# tviibh16m register map
Vendor: Infineon Technologies; Series: TVIIBH16M; File version: 1.0
CPU: CM7 r0p1, little endian, MPU, FPU, double-precision FPU, I-cache, D-cache, VTOR, ITCM, DTCM, 3 interrupt priority bits, 16 interrupts
Registers are 32-bit, read-write, reset 0x0 unless marked. A register's access mark holds for its fields unless they carry their own. Offsets are from the block's base; [hi:lo] are bit positions; lines under a group give offsets from that group.

## SDHC0 (part 1 of 3) — SD/eMMC Host Controller
Base 0x40460000
0x1000 CORE group — MMIO for Synopsys Mobile Storage Host Controller IP
  0x00 SDMASA_R — SDMA System Address register
    [31:0] BLOCKCNT_SDMASA — 32-bit Block Count (SDMA System Address) - SDMA System Address (Host Version 4 Enable = 0): This register contains the system memory address for an SDMA transfer in the 32-bit addressing mode. When the Host Controller stops an SDMA transfer, this register points to the system address of the next contiguous data position. It can be accessed only if no transaction is executing. Reading this register during data transfers may return an invalid value. - 32-bit Block Count (Host Version 4 Enable = 1): From the Host Controller Version 4.10 specification, this register is redefined as 32-bit Block Count. The Host Controller decrements the block count of this register for every block transfer and the data transfer stops when the count reaches zero. This register must be accessed when no transaction is executing. Reading this register during data transfers may return invalid value. Following are the values for BLOCKCNT_SDMASA: - 0xFFFF_FFFF - 4G - 1 Block - ...... - 0x0000_0002 - 2 Blocks - 0x0000_0001 - 1 Block - 0x0000_0000 - Stop Count Note: - When Host Version 4 Enable = 0, SDMA uses this register as system address and hence Auto CMD23 cannot be used with SDMA since this register is assigned for Auto CMD23 as 32-bit Block Count register. -When Host Version 4 Enable = 1, SDMA uses ADMA system address register and this register is reassigned to 32-bit Block Count. This register must be programmed with a non-zero value for data transfer if the 32-bit Block count register is used instead of the 16-bit Block count register. SDMA may use Auto CMD23 if 32-bit Block Count register is used.
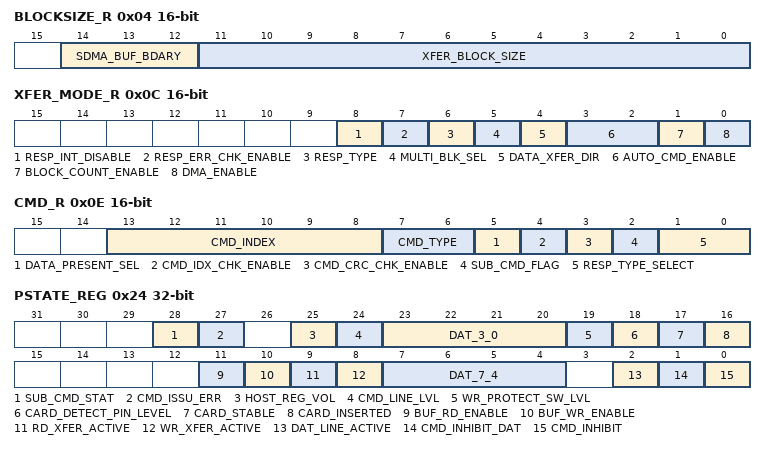
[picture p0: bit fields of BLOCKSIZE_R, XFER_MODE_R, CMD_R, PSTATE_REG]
  0x04 BLOCKSIZE_R 16-bit — Block Size register
    [14:12] SDMA_BUF_BDARY — SDMA Buffer Boundary These bits specify the size of contiguous buffer in system memory. The SDMA transfer waits at every boundary specified by these fields and the Host Controller generates the DMA interrupt to request the Host Driver to update the SDMA System Address register. Values: - 0x0 (BYTES_4K): 4K bytes SDMA Buffer Boundary - 0x1 (BYTES_8K): 8K bytes SDMA Buffer Boundary - 0x2 (BYTES_16K): 16K bytes SDMA Buffer Boundary - 0x3 (BYTES_32K): 32K bytes SDMA Buffer Boundary - 0x4 (BYTES_64K): 64K bytes SDMA Buffer Boundary - 0x5 (BYTES_128K): 128K bytes SDMA Buffer Boundary - 0x6 (BYTES_256K): 256K bytes SDMA Buffer Boundary - 0x7 (BYTES_512K): 512K bytes SDMA Buffer Boundary
    [11:0] XFER_BLOCK_SIZE — Transfer Block Size These bits specify the block size of data transfers. In case of memory, it is set to 512 bytes. It can be accessed only if no transaction is executing. Read operations during transfers may return an invalid value, and write operations are ignored. Following are the values for XFER_BLOCK_SIZE: - 0x1: 1 byte - 0x2: 2 bytes - 0x3: 3 bytes - ...... - 0x1FF: 511 byte - 0x200: 512 bytes - ...... - 0x800: 2048 bytes Note: This register must be programmed with a non-zero value for data transfer.
  0x06 BLOCKCOUNT_R 16-bit — 16-bit Block Count register
    [15:0] BLOCK_CNT — 16-bit Block Count - If the Host Version 4 Enable bit is set 0 or the 16-bit Block Count register is set to non-zero, the 16-bit Block Count register is selected. - If the Host Version 4 Enable bit is set 1 and the 16-bit Block Count register is set to zero, the 32-bit Block Count register is selected. Following are the values for BLOCK_CNT: - 0x0: Stop Count - 0x1: 1 Block - 0x2: 2 Blocks - ... - ... - 0xFFFF: 65535 Blocks Note: For Host Version 4 Enable = 0, this register must be set to 0000h before programming the 32-bit block count register when Auto CMD23 is enabled for non-DMA and ADMA modes.
  0x08 ARGUMENT_R — Argument register
    [31:0] ARGUMENT — Command Argument These bits specify the SD/eMMC command argument that is specified in bits 39-8 of the Command format.
  0x0C XFER_MODE_R 16-bit — Transfer Mode register
    [8] RESP_INT_DISABLE — Response Interrupt Disable The Host Controller supports response check function to avoid overhead of response error check by the Host driver. Response types of only R1 and R5 can be checked by the Controller. If Host Driver checks the response error, set this bit to 0 and wait for Command Complete Interrupt and then check the response register. If the Host Controller checks the response error, set this bit to 1 and set the Response Error Check Enable bit to 1. The Command Complete Interrupt is disabled by this bit regardless of the Command Complete Signal Enable. Values: - 0x0 (ENABLED): Response Interrupt is enabled - 0x1 (DISABLED): Response Interrupt is disabled
    [7] RESP_ERR_CHK_ENABLE — Response Error Check Enable The Host Controller supports response check function to avoid overhead of response error check by Host driver. Response types of only R1 and R5 can be checked by the Controller. If the Host Controller checks the response error, set this bit to 1 and set Response Interrupt Disable to 1. If an error is detected, the Response Error interrupt is generated in the Error Interrupt Status register. Note: - Response error check must not be enabled for any response type other than R1 and R5. Values: - 0x0 (DISABLED): Response Error Check is disabled - 0x1 (ENABLED): Response Error Check is enabled
    [6] RESP_TYPE — Response Type R1/R5 This bit selects either R1 or R5 as a response type when the Response Error Check is selected. Error statuses checked in R1: - OUT_OF_RANGE - ADDRESS_ERROR - BLOCK_LEN_ERROR - WP_VIOLATION - CARD_IS_LOCKED - COM_CRC_ERROR - CARD_ECC_FAILED - CC_ERROR - ERROR Response Flags checked in R5: - COM_CRC_ERROR - ERROR - FUNCTION_NUMBER - OUT_OF_RANGE Values: - 0x0 (RESP_R1): R1 (Memory) - 0x1 (RESP_R5): R5 (SDIO)
    [5] MULTI_BLK_SEL — Multi/Single Block Select This bit is set when issuing multiple-block transfer commands using the DAT line. If this bit is set to 0, it is not necessary to set the Block Count register.
    [4] DATA_XFER_DIR — Data Transfer Direction Select This bit defines the direction of DAT line data transfers. This bit is set to 1 by the Host Driver to transfer data from the SD/eMMC card to the Host Controller and it is set to 0 for all other commands. Values: - 0x1 (READ): Read (Card to Host) - 0x0 (WRITE): Write (Host to Card)
    [3:2] AUTO_CMD_ENABLE — Auto Command Enable This field determines use of Auto Command functions. Note: In SDIO, this field must be set as 00b (Auto Command Disabled). Values: - 0x0 (AUTO_CMD_DISABLED): Auto Command Disabled - 0x1 (AUTO_CMD12_ENABLED): Auto CMD12 Enable - 0x2 (AUTO_CMD23_ENABLED): Auto CMD23 Enable - 0x3 (AUTO_CMD_AUTO_SEL): Auto CMD Auto Select
    [1] BLOCK_COUNT_ENABLE — Block Count Enable This bit is used to enable the Block Count register, which is relevant for multiple block transfers. If this bit is set to 0, the Block Count register is disabled, which is useful in executing an infinite transfer. The Host Driver must set this bit to 0 when ADMA is used. When 16-bit Block Count register is used, the Host Driver can set this bit to 0 in ADMA2 mode to enable larger data transfer than the maximum of 65535 block counts supported by the 16-bit Block Count register.
    [0] DMA_ENABLE — DMA Enable This bit enables the DMA functionality. If this bit is set to 1, a DMA operation begins when the Host Driver writes to the Command register. You can select one of the DMA modes by using DMA Select in the Host Control 1 register. Values: - 0x1 (ENABLED): DMA Data transfer - 0x0 (DISABLED): No data transfer or Non-DMA data transfer
  0x0E CMD_R 16-bit — Command register
    [13:8] CMD_INDEX — Command Index These bits are set to the command number that is specified in bits 45-40 of the Command Format.
    [7:6] CMD_TYPE — Command Type These bits indicate the command type. Note: While issuing Abort CMD using CMD12/CMD52 or reset CMD using CMD0/CMD52, CMD_TYPE field shall be set to 0x3. Values: - 0x3 (ABORT_CMD): Abort - 0x2 (RESUME_CMD): Resume - 0x1 (SUSPEND_CMD): Suspend - 0x0 (NORMAL_CMD): Normal
    [5] DATA_PRESENT_SEL — Data Present Select This bit is set to 1 to indicate that data is present and that the data is transferred using the DAT line. This bit is set to 0 in the following instances: - Command using the CMD line - Command with no data transfer but using busy signal on the DAT[0] line - Resume Command Values: - 0x0 (NO_DATA): No Data Present - 0x1 (DATA): Data Present
    [4] CMD_IDX_CHK_ENABLE — Command Index Check Enable This bit enables the Host Controller to check the index field in the response to verify if it has the same value as the command index. If the value is not the same, it is reported as a Command Index error. Note: - Index Check enable must be set to 0 for the command with no response, R2 response, R3 response and R4 response. Values: - 0x0 (DISABLED): Disable - 0x1 (ENABLED): Enable
    [3] CMD_CRC_CHK_ENABLE — Command CRC Check Enable This bit enables the Host Controller to check the CRC field in the response. If an error is detected, it is reported as a Command CRC error. Note: - CRC Check enable must be set to 0 for the command with no response, R3 response, and R4 response. Values: - 0x0 (DISABLED): Disable - 0x1 (ENABLED): Enable
    [2] SUB_CMD_FLAG — Sub Command Flag This bit distinguishes between a main command and a sub command. Values: - 0x0 (MAIN): Main Command - 0x1 (SUB): Sub Command
    [1:0] RESP_TYPE_SELECT — Response Type Select This bit indicates the type of response expected from the card. Values: - 0x0 (NO_RESP): No Response - 0x1 (RESP_LEN_136): Response Length 136 - 0x2 (RESP_LEN_48): Response Length 48 - 0x3 (RESP_LEN_48B): Response Length 48; Check Busy after response
  0x10 RESP01_R ro — Response Register 0/1
    [31:0] RESP01 — Command Response These bits reflect 39-8 bits of SD/eMMC Response Field. Note: For Auto CMD, the 32-bit response (bits 39-8 of the Response Field) is updated in the RESP67_R register.
  0x14 RESP23_R ro — Response Register 2/3
    [31:0] RESP23 — Command Response These bits reflect 71-40 bits of the SD/eMMC Response
  0x18 RESP45_R ro — Response Register 4/5
    [31:0] RESP45 — Command Response These bits reflect 103-72 bits of the Response Field.
  0x1C RESP67_R ro — Response Register 6/7
    [31:0] RESP67 — Command Response These bits reflect bits 135-104 of SD/EMMC Response Field. Note: For Auto CMD, this register also reflects the 32-bit response (bits 39-8 of the Response Field).
  0x20 BUF_DATA_R — Buffer Data Port Register
    [31:0] BUF_DATA — Buffer Data These bits enable access to the Host Controller packet buffer.
  0x24 PSTATE_REG ro — Present State Register
    [28] SUB_CMD_STAT — Sub Command Status This bit is used to distinguish between a main command and a sub command status. Values: - 0x0 (FALSE): Main Command Status - 0x1 (TRUE): Sub Command Status
    [27] CMD_ISSU_ERR — Command Not Issued by Error This bit is set if a command cannot be issued after setting the command register due to an error except the Auto CMD12 error. Values: - 0x0 (FALSE): No error for issuing a command - 0x1 (TRUE): Command cannot be issued
    [25] HOST_REG_VOL — Host Regulator Voltage Stable This bit is used to check whether the host regulator voltage is stable for switching the voltage of UHS-I mode. This bit reflects the synchronized value of the host_reg_vol_stable signal. Values: - 0x0 (FALSE): Host Regulator Voltage is not stable - 0x1 (TRUE): Host Regulator Voltage is stable
    [24] CMD_LINE_LVL — Command-Line Signal Level This bit is used to check the CMD line level to recover from errors and for debugging. These bits reflect the value of the sd_cmd_in signal.
    [23:20] DAT_3_0 — DAT[3:0] Line Signal Level This bit is used to check the DAT line level to recover from errors and for debugging. These bits reflect the value of the sd_dat_in (lower nibble) signal.
    [19] WR_PROTECT_SW_LVL — Write Protect Switch Pin Level This bit is supported only for memory and combo cards. This bit reflects the synchronized value of the card_write_prot signal. Values: - 0x0 (FALSE): Write protected - 0x1 (TRUE): Write enabled
    [18] CARD_DETECT_PIN_LEVEL — Card Detect Pin Level This bit reflects the inverse synchronized value of the card_detect_n signal. Values: - 0x0 (FALSE): No card present - 0x1 (TRUE): Card Present
    [17] CARD_STABLE — Card Stable This bit indicates the stability of the Card Detect Pin Level. A card is not detected if this bit is set to 1 and the value of the CARD_INSERTED bit is 0. Values: - 0x0 (FALSE): Reset or Debouncing - 0x1 (TRUE): No Card or Inserted
    [16] CARD_INSERTED — Card Inserted This bit indicates whether a card has been inserted. The Host Controller debounces this signal so that Host Driver need not wait for it to stabilize. Values: - 0x0 (FALSE): Reset, Debouncing, or No card - 0x1 (TRUE): Card Inserted
    [11] BUF_RD_ENABLE — Buffer Read Enable This bit is used for non-DMA transfers. This bit is set if valid data exists in the Host buffer. Values: - 0x0 (DISABLED): Read disable - 0x1 (ENABLED): Read enable
    [10] BUF_WR_ENABLE — Buffer Write Enable This bit is used for non-DMA transfers. This bit is set if space is available for writing data. Values: - 0x0 (DISABLED): Write disable - 0x1 (ENABLED): Write enable
    [9] RD_XFER_ACTIVE — Read Transfer Active This bit indicates whether a read transfer is active for SD/eMMC mode. Values: - 0x0 (INACTIVE): No valid data - 0x1 (ACTIVE): Transferring data
    [8] WR_XFER_ACTIVE — Write Transfer Active This status indicates whether a write transfer is active for SD/eMMC mode. Values: - 0x0 (INACTIVE): No valid data - 0x1 (ACTIVE): Transferring data
    [7:4] DAT_7_4 — DAT[7:4] Line Signal Level This bit is used to check the DAT line level to recover from errors and for debugging. These bits reflect the value of the sd_dat_in (upper nibble) signal.
    [2] DAT_LINE_ACTIVE — DAT Line Active (SD/eMMC Mode only) This bit indicates whether one of the DAT lines on the SD/eMMC bus is in use. In the case of read transactions, this bit indicates whether a read transfer is executing on the SD/eMMC bus. In the case of write transactions, this bit indicates whether a write transfer is executing on the SD/eMMC bus. For a command with busy, this status indicates whether the command executing busy is executing on an SD or eMMC bus. Values: - 0x0 (INACTIVE): DAT Line Inactive - 0x1 (ACTIVE): DAT Line Active
    [1] CMD_INHIBIT_DAT — Command Inhibit (DAT) This bit is applicable for SD/eMMC mode and is generated if either DAT line active or Read transfer active is set to 1. If this bit is set to 0, it indicates that the Host Controller can issue subsequent SD/eMMC commands. Values: - 0x0 (READY): Can issue command which used DAT line - 0x1 (NOT_READY): Cannot issue command which used DAT line
    [0] CMD_INHIBIT — Command Inhibit (CMD) This bit indicates the following : - SD/eMMC mode: If this bit is set to 0, it indicates that the CMD line is not in use and the Host controller can issue an SD/eMMC command using the CMD line. This bit is set when the command register is written. This bit is cleared when the command response is received. This bit is not cleared by the response of auto CMD12/23 but cleared by the response of read/write command. Values: - 0x0 (READY): Host Controller is ready to issue a command - 0x1 (NOT_READY): Host Controller is not ready to issue a command
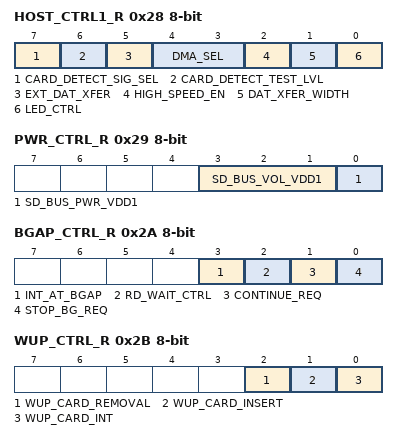
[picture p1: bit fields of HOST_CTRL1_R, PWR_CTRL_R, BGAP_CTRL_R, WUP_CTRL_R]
  0x28 HOST_CTRL1_R 8-bit — Host Control 1 Register
    [7] CARD_DETECT_SIG_SEL — Card Detect Signal Selection This bit selects a source for card detection. When the source for the card detection is switched, the interrupt must be disabled during the switching period. Values: - 0x1 (CARD_DT_TEST_LEVEL): Card Detect Test Level is selected (for test purpose) - 0x0 (card_detect_n): card_detect_n signal is selected (for normal use)
    [6] CARD_DETECT_TEST_LVL — Card Detect Test Level This bit is enabled while the Card Detect Signal Selection is set to 1 and it indicates whether a card inserted or not. Values: - 0x1 (CARD_INSERTED): Card Inserted - 0x0 (No_CARD): No Card
    [5] EXT_DAT_XFER — Extended Data Transfer Width This bit controls 8-bit bus width mode of embedded device. Values: - 0x1 (EIGHT_BIT): 8-bit Bus Width - 0x0 (DEFAULT): Bus Width is selected by the Data Transfer Width
    [4:3] DMA_SEL
    [2] HIGH_SPEED_EN — High Speed Enable (SD/eMMC Mode only) Before setting this bit, the Host Driver checks the High Speed Support in the Capabilities register. Note: SDHC always outputs the sd_cmd_out and sd_dat_out lines at the rising edge of card clock irrespective of this bit. Values: - 0x1 (HIGH_SPEED): High Speed mode - 0x0 (NORMAL_SPEED): Normal Speed mode
    [1] DAT_XFER_WIDTH — Data Transfer Width For SD/eMMC mode,this bit selects the data transfer width of the Host Controller. The Host Driver sets it to match the data width of the SD/eMMC card. Values: - 0x1 (FOUR_BIT): 4-bit mode - 0x0 (ONE_BIT): 1-bit mode
    [0] LED_CTRL — LED Control This bit is used to caution the user not to remove the card while the SD card is being accessed. The value is reflected on the led_ctrl ouput. Values: - 0x0 (OFF): LED off - 0x1 (ON): LED on
  0x29 PWR_CTRL_R 8-bit — Power Control Register
    [3:1] SD_BUS_VOL_VDD1 — These bits are NON-operational (they can be written and read but they have no effect). In a generic HCI host these would select the card supply voltage. But, for the applications targeted for this block it is assumed that the card supply voltage is always fixed at the board level. If for some reason there is a variable power supply then that can be managed through normal GPIO programming separately.
    [0] SD_BUS_PWR_VDD1 — SD Bus Power for VDD1 This bit enables VDD1 power of the card. This setting is available on the card_if_pwr_en output so that it can be used to control the VDD1 power supply of the card. Before setting this bit, the SD Host Driver sets the SD Bus Voltage Select bit. If the Host Controller detects a No Card state, this bit is cleared. In SD mode, if this bit is cleared, the Host Controller stops the SD Clock by clearing the SD_CLK_IN bit in the CLK_CTRL_R register. Values: - 0x0 (OFF): Power off - 0x1 (ON): Power on
  0x2A BGAP_CTRL_R 8-bit — Block Gap Control Register
    [3] INT_AT_BGAP — Interrupt At Block Gap This bit is valid only in the 4-bit mode of an SDIO card and is used to select a sample point in the interrupt cycle. Setting to 1 enables interrupt detection at the block gap for a multiple block transfer. Values: - 0x0 (DISABLE): Disabled - 0x1 (ENABLE): Enabled
    [2] RD_WAIT_CTRL
    [1] CONTINUE_REQ — Continue Request This bit is used to restart the transaction, which was stopped using the Stop At Block Gap Request. The Host Controller automatically clears this bit when the transaction restarts. If stop at block gap request is set to 1, any write to this bit is ignored. Values: - 0x0 (NO_AFFECT): No Affect - 0x1 (RESTART): Restart
    [0] STOP_BG_REQ — Stop At Block Gap Request This bit is used to stop executing read and write transactions at the next block gap for non-DMA, SDMA, and ADMA transfers. Values: - 0x0 (XFER): Transfer - 0x1 (STOP): Stop
  0x2B WUP_CTRL_R 8-bit — Wakeup Control Register
    [2] WUP_CARD_REMOVAL — Wakeup Event Enable on SD Card Removal This bit enables wakeup event through Card Removal assertion in the Normal Interrupt Status register. For the SDIO card, Wake Up Support (FN_WUS) in the Card Information Structure (CIS) register does not affect this bit. Values: - 0x0 (DISABLED): Disable - 0x1 (ENABLED): Enable
    [1] WUP_CARD_INSERT — Wakeup Event Enable on SD Card Insertion This bit enables wakeup event through Card Insertion assertion in the Normal Interrupt Status register. FN_WUS (Wake Up Support) in CIS does not affect this bit. Values: - 0x0 (DISABLED): Disable - 0x1 (ENABLED): Enable
    [0] WUP_CARD_INT — Wakeup Event Enable on SDIO Card Interrupt (through DAT[1]). This bit enables wakeup event through an SDIO Card Interrupt assertion in the Normal Interrupt Status register. This bit can be set to 1 if FN_WUS (Wake Up Support) in CIS is set to 1. Values: - 0x0 (DISABLED): Disable - 0x1 (ENABLED): Enable
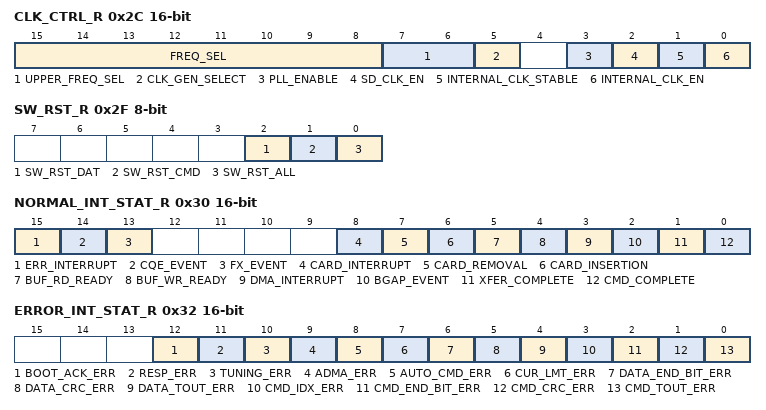
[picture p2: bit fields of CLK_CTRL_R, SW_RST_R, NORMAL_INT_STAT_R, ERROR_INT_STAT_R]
  0x2C CLK_CTRL_R 16-bit — Clock Control Register
    [15:8] FREQ_SEL — SDCLK Frequency Select These bits are used to select the frequency of the SDCLK signal. 10-bit Divided Clock Mode: - 0x3FF - 1/2046 Divided clock - .......... - N - 1/2N Divided Clock - .......... - 0x002 - 1/4 Divided Clock - 0x001 - 1/2 Divided Clock - 0x000 - Base clock (10MHz - 255 MHz)
    [7:6] UPPER_FREQ_SEL — These bits specify the upper 2 bits of 10-bit SDCLK Frequency Select control.
    [5] CLK_GEN_SELECT — Clock Generator Select This bit is used to select the clock generator mode in SDCLK Frequency Select. Values: - 0x0 (FALSE): Divided Clock Mode - 0x1 (TRUE): Programmable Clock Mode
    [3] PLL_ENABLE — PLL Enable This bit is used to activate the PLL (applicable when Host Version 4 Enable = 1). Values: - 0x0 (FALSE): PLL is in low power mode - 0x1 (TRUE): PLL is enabled
    [2] SD_CLK_EN — SD/eMMC Clock Enable This bit stops the clk_card output when set to 0. The SDCLK Frequency Select bit can be changed when this bit is set to 0. Values: - 0x0 (FALSE): Disable providing clk_card - 0x1 (TRUE): Enable providing clk_card
    [1] INTERNAL_CLK_STABLE ro — Internal Clock Stable This bit enables the Host Driver to check the clock stability twice after the Internal Clock Enable bit is set and after the PLL Enable bit is set. This bit reflects the synchronized value of the Internal Clock Stable signal after the Internal Clock Enable bit is set to 1 and also reflects the synchronized value of the Card Clock Stable signal after the PLL Enable bit is set to 1. Values: - 0x0 (FALSE): Not Ready - 0x1 (TRUE): Ready
    [0] INTERNAL_CLK_EN — Internal Clock Enable This bit is set to 0 when the Host Driver is not using the Host Controller or the Host Controller awaits a wakeup interrupt. The Host Controller must stop its internal clock to enter a very low power state. Certain registers are not accessible when this bit is off. So, to be safe turn it on for any register access. Values: - 0x0 (FALSE): Stop - 0x1 (TRUE): Oscillate
  0x2E TOUT_CTRL_R 8-bit — Timeout Control Register
    [3:0] TOUT_CNT
  0x2F SW_RST_R 8-bit — Software Reset Register
    [2] SW_RST_DAT — Software Reset For DAT line This bit is used in SD/eMMC mode and it resets only a part of the data circuit and the DMA circuit is also reset. The following registers and bits are cleared by this bit: - Buffer Data Port register - Buffer is cleared and initialized. - Present state register - Buffer Read Enable - Buffer Write Enable - Read Transfer Active - Write Transfer Active - DAT Line Active - Command Inhibit (DAT) - Block Gap Control register - Continue Request - Stop At Block Gap Request - Normal Interrupt status register - Buffer Read Ready - Buffer Write Ready - DMA Interrupt - Block Gap Event - Transfer Complete Values: - 0x0 (FALSE): Work - 0x1 (TRUE): Reset
    [1] SW_RST_CMD — Software Reset For CMD line This bit resets only a part of the command circuit to be able to issue a command. This reset is effective only for a command issuing circuit (including response error statuses related to Command Inhibit (CMD) control) and does not affect the data transfer circuit. Host Controller can continue data transfer even after this reset is executed while handling subcommand-response errors. The following registers and bits are cleared by this bit: - Present State register - Command Inhibit (CMD) bit - Normal Interrupt Status register - Command Complete bit - Error Interrupt Status - Response error statuses related to Command Inhibit (CMD) bit Values: - 0x0 (FALSE): Work - 0x1 (TRUE): Reset
    [0] SW_RST_ALL — Software Reset For All This reset affects the entire Host Controller except for the card detection circuit. During its initialization, the Host Driver sets this bit to 1 to reset the Host Controller. All registers are reset except the capabilities register. If this bit is set to 1, the Host Driver must issue reset command and reinitialize the card. Values: - 0x0 (FALSE): Work - 0x1 (TRUE): Reset
  0x30 NORMAL_INT_STAT_R 16-bit — Normal Interrupt Status Register
    [15] ERR_INTERRUPT ro — Error Interrupt If any of the bits in the Error Interrupt Status register are set, then this bit is set. Values: - 0x0 (FALSE): No Error - 0x1 (TRUE): Error
    [14] CQE_EVENT write-1-clears — Command Queuing Event This status is set if Command Queuing/Crypto related event has occurred in eMMC/SD mode. Read CQHCI's CQIS/CRNQIS register for more details. In UHS-II Mode, this bit is irrelevant. Values: - 0x0 (FALSE): No Event - 0x1 (TRUE): Command Queuing Event is detected
    [13] FX_EVENT ro — FX Event This status is set when R[14] of response register is set to 1 and Response Type R1/R5 is set to 0 in Transfer Mode register. This interrupt is used with response check function. Values: - 0x0 (FALSE): No Event - 0x1 (TRUE): FX Event is detected
    [8] CARD_INTERRUPT ro — Card Interrupt This bit reflects the synchronized value of: - DAT[1] Interrupt Input for SD Mode Values: - 0x0 (FALSE): No Card Interrupt - 0x1 (TRUE): Generate Card Interrupt
    [7] CARD_REMOVAL write-1-clears — Card Removal This bit is set if the Card Inserted in the Present State register changes from 1 to 0. Values: - 0x0 (FALSE): Card state stable or Debouncing - 0x1 (TRUE): Card Removed
    [6] CARD_INSERTION write-1-clears — Card Insertion This bit is set if the Card Inserted in the Present State register changes from 0 to 1. Values: - 0x0 (FALSE): Card state stable or Debouncing - 0x1 (TRUE): Card Inserted
    [5] BUF_RD_READY write-1-clears — Buffer Read Ready This bit is set if the Buffer Read Enable changes from 0 to 1. Values: - 0x0 (FALSE): Not ready to read buffer - 0x1 (TRUE): Ready to read buffer
    [4] BUF_WR_READY write-1-clears — Buffer Write Ready This bit is set if the Buffer Write Enable changes from 0 to 1. Values: - 0x0 (FALSE): Not ready to write buffer - 0x1 (TRUE): Ready to write buffer
    [3] DMA_INTERRUPT write-1-clears — DMA Interrupt This bit is set if the Host Controller detects the SDMA Buffer Boundary during transfer. In case of ADMA, by setting the Int field in the descriptor table, the Host controller generates this interrupt. This interrupt is not generated after a Transfer Complete. Values: - 0x0 (FALSE): No DMA Interrupt - 0x1 (TRUE): DMA Interrupt is generated
    [2] BGAP_EVENT write-1-clears — Block Gap Event This bit is set when both read/write transaction is stopped at block gap due to a Stop at Block Gap Request. Values: - 0x0 (FALSE): No Block Gap Event - 0x1 (TRUE): Transaction stopped at block gap
    [1] XFER_COMPLETE write-1-clears — Transfer Complete This bit is set when a read/write transfer and a command with status busy is completed. Values: - 0x0 (FALSE): Not complete - 0x1 (TRUE): Command execution is completed
    [0] CMD_COMPLETE write-1-clears — Command Complete In an SD/eMMC Mode, this bit is set when the end bit of a response except for Auto CMD12 and Auto CMD23. This interrupt is not generated when the Response Interrupt Disable in Transfer Mode Register is set to 1. Values: - 0x0 (FALSE): No command complete - 0x1 (TRUE): Command Complete
  0x32 ERROR_INT_STAT_R 16-bit — Error Interrupt Status Register
    [12] BOOT_ACK_ERR write-1-clears — Boot Acknowledgement Error This bit is set when there is a timeout for boot acknowledgement or when detecting boot ack status having a value other than 010. This is applicable only when boot acknowledgement is expected in eMMC mode. In SD mode, this bit is irrelevant. Values: - 0x0 (FALSE): No error - 0x1 (TRUE): Error
    [11] RESP_ERR write-1-clears — Response Error Host Controller Version 4.00 supports response error check function to avoid overhead of response error check by Host Driver during DMA execution. If Response Error Check Enable is set to 1 in the Transfer Mode register, Host Controller Checks R1 or R5 response. If an error is detected in a response, this bit is set to 1.This is applicable in SD/eMMC mode. Values: - 0x0 (FALSE): No error - 0x1 (TRUE): Error
    [10] TUNING_ERR write-1-clears
    [9] ADMA_ERR write-1-clears — ADMA Error This bit is set when the Host Controller detects error during ADMA-based data transfer. The error could be due to following reasons: - Error response received from System bus (Master I/F) - ADMA3,ADMA2 Descriptors invalid - CQE Task or Transfer descriptors invalid When the error occurs, the state of the ADMA is saved in the ADMA Error Status register. In eMMC CQE mode: The Host Controller generates this Interrupt when it detects an invalid descriptor data (Valid=0) at the ST_FDS state. ADMA Error State in the ADMA Error Status indicates that an error has occurred in ST_FDS state. The Host Driver may find that Valid bit is not set at the error descriptor. Values: - 0x0 (FALSE): No error - 0x1 (TRUE): Error
    [8] AUTO_CMD_ERR write-1-clears — Auto CMD Error This error status is used by Auto CMD12 and Auto CMD23 in SD/eMMC mode. This bit is set when detecting that any of the bits D00 to D05 in Auto CMD Error Status register has changed from 0 to 1. D07 is effective in case of Auto CMD12. Auto CMD Error Status register is valid while this bit is set to 1 and may be cleared by clearing of this bit. Values: - 0x0 (FALSE): No error - 0x1 (TRUE): Error
    [7] CUR_LMT_ERR write-1-clears — Current Limit Error By setting the SD Bus Power bit in the Power Control register, the Host Controller is requested to supply power for the SD Bus. If the Host Controller supports the Current Limit function, it can be protected from an illegal card by stopping power supply to the card in which case this bit indicates a failure status. A reading of 1 for this bit means that the Host Controller is not supplying power to the SD card due to some failure. A reading of 0 for this bit means that the Host Controller is supplying power and no error has occurred. The Host Controller may require some sampling time to detect the current limit. DWC_mshc Host Controller does not support this function, this bit is always set to 0. Values: - 0x0 (FALSE): No error - 0x1 (TRUE): Power Fail
    [6] DATA_END_BIT_ERR write-1-clears — Data End Bit Error This error occurs in SD/eMMC mode either when detecting 0 at the end bit position of read data that uses the DAT line or at the end bit position of the CRC status. Values: - 0x0 (FALSE): No error - 0x1 (TRUE): Error
    [5] DATA_CRC_ERR write-1-clears — Data CRC Error This error occurs in SD/eMMC mode when detecting CRC error when transferring read data which uses the DAT line, when detecting the Write CRC status having a value of other than 010 or when write CRC status timeout. Values: - 0x0 (FALSE): No error - 0x1 (TRUE): Error
    [4] DATA_TOUT_ERR write-1-clears — Data Timeout Error This bit is set in SD/eMMC mode when detecting one of the following timeout conditions: - Busy timeout for R1b, R5b type - Busy timeout after Write CRC status - Write CRC Status timeout - Read Data timeout Values: - 0x0 (FALSE): No error - 0x1 (TRUE): Time out
    [3] CMD_IDX_ERR write-1-clears — Command Index Error This bit is set if a Command Index error occurs in the command respons in SD/eMMC mode. Values: - 0x0 (FALSE): No error - 0x1 (TRUE): Error
    [2] CMD_END_BIT_ERR write-1-clears — Command End Bit Error This bit is set when detecting that the end bit of a command response is 0 in SD/eMMC mode. Values: - 0x0 (FALSE): No error - 0x1 (TRUE): End Bit error generated
    [1] CMD_CRC_ERR write-1-clears — Command CRC Error Command CRC Error is generated in SD/eMMC mode for following two cases. - If a response is returned and the Command Timeout Error is set to 0 (indicating no timeout), this bit is set to 1 when detecting a CRC error in the command response. - The Host Controller detects a CMD line conflict by monitoring the CMD line when a command is issued. If the Host Controller drives the CMD line to 1 level, but detects 0 level on the CMD line at the next SD clock edge, then the Host Controller aborts the command (stop driving CMD line) and set this bit to 1. The Command Timeout Error is also set to 1 to distinguish a CMD line conflict. Values: - 0x0 (FALSE): No error - 0x1 (TRUE): CRC error generated
    [0] CMD_TOUT_ERR write-1-clears — Command Timeout Error In SD/eMMC Mode,this bit is set only if no response is returned within 64 SD clock cycles from the end bit of the command. If the Host Controller detects a CMD line conflict, along with Command CRC Error bit, this bit is set to 1, without waiting for 64 SD/eMMC card clock cycles. Values: - 0x0 (FALSE): No error - 0x1 (TRUE): Time out
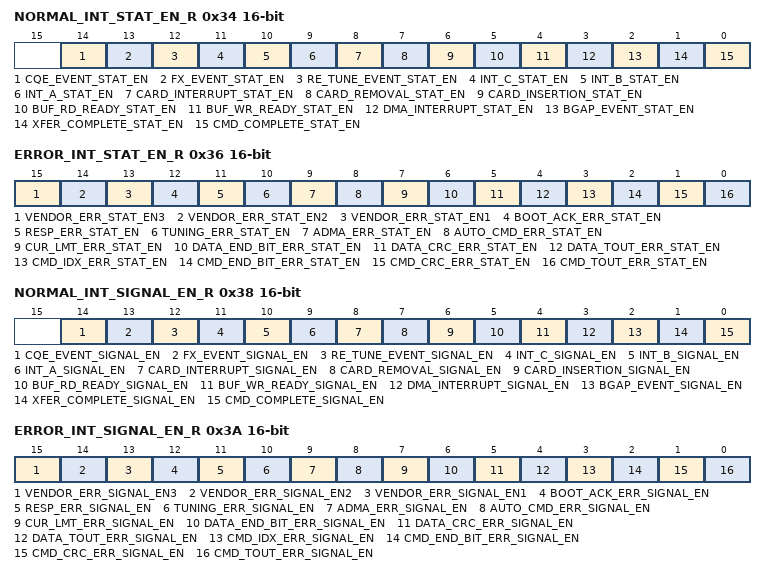
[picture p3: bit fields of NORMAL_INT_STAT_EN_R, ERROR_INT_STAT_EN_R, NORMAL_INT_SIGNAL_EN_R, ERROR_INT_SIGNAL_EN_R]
  0x34 NORMAL_INT_STAT_EN_R 16-bit — Normal Interrupt Status Enable Register
    [14] CQE_EVENT_STAT_EN — CQE Event Status Enable Values: - 0x0 (FALSE): Masked - 0x1 (TRUE): Enabled
    [13] FX_EVENT_STAT_EN — FX Event Status Enable This bit is added from Version 4.10. Values: - 0x0 (FALSE): Masked - 0x1 (TRUE): Enabled
    [12] RE_TUNE_EVENT_STAT_EN
    [11] INT_C_STAT_EN
    [10] INT_B_STAT_EN
    [9] INT_A_STAT_EN
    [8] CARD_INTERRUPT_STAT_EN — Card Interrupt Status Enable If this bit is set to 0, the Host Controller clears the interrupt request to the System. The Card Interrupt detection is stopped when this bit is cleared and restarted when this bit is set to 1. The Host Driver may clear the Card Interrupt Status Enable before servicing the Card Interrupt and may set this bit again after all interrupt requests from the card are cleared to prevent inadvertent interrupts. Values: - 0x0 (FALSE): Masked - 0x1 (TRUE): Enabled
    [7] CARD_REMOVAL_STAT_EN — Card Removal Status Enable Values: - 0x0 (FALSE): Masked - 0x1 (TRUE): Enabled
    [6] CARD_INSERTION_STAT_EN — Card Insertion Status Enable Values: - 0x0 (FALSE): Masked - 0x1 (TRUE): Enabled
    [5] BUF_RD_READY_STAT_EN — Buffer Read Ready Status Enable Values: - 0x0 (FALSE): Masked - 0x1 (TRUE): Enabled
    [4] BUF_WR_READY_STAT_EN — Buffer Write Ready Status Enable Values: - 0x0 (FALSE): Masked - 0x1 (TRUE): Enabled
    [3] DMA_INTERRUPT_STAT_EN — DMA Interrupt Status Enable Values: - 0x0 (FALSE): Masked - 0x1 (TRUE): Enabled
    [2] BGAP_EVENT_STAT_EN — Block Gap Event Status Enable Values: - 0x0 (FALSE): Masked - 0x1 (TRUE): Enabled
    [1] XFER_COMPLETE_STAT_EN — Transfer Complete Status Enable Values: - 0x0 (FALSE): Masked - 0x1 (TRUE): Enabled
    [0] CMD_COMPLETE_STAT_EN — Command Complete Status Enable Values: - 0x0 (FALSE): Masked - 0x1 (TRUE): Enabled
  0x36 ERROR_INT_STAT_EN_R 16-bit — Error Interrupt Status Enable Register
    [15] VENDOR_ERR_STAT_EN3
    [14] VENDOR_ERR_STAT_EN2
    [13] VENDOR_ERR_STAT_EN1
    [12] BOOT_ACK_ERR_STAT_EN — Boot Acknowledgment Error (eMMC Mode only) Setting this bit to 1 enables setting of Boot Acknowledgment Error in Error Interrupt Status register (ERROR_INT_STAT_R). Values: - 0x0 (FALSE): Masked - 0x1 (TRUE): Enabled
    [11] RESP_ERR_STAT_EN — Response Error Status Enable (SD Mode only) Values: - 0x0 (FALSE): Masked - 0x1 (TRUE): Enabled
    [10] TUNING_ERR_STAT_EN — Tuning Error Status Enable (UHS-I Mode only) Values: - 0x0 (FALSE): Masked - 0x1 (TRUE): Enabled
    [9] ADMA_ERR_STAT_EN — ADMA Error Status Enable Values: - 0x0 (FALSE): Masked - 0x1 (TRUE): Enabled
    [8] AUTO_CMD_ERR_STAT_EN — Auto CMD Error Status Enable (SD/eMMC Mode only). Values: - 0x0 (FALSE): Masked - 0x1 (TRUE): Enabled
    [7] CUR_LMT_ERR_STAT_EN — Current Limit Error Status Enable Values: - 0x0 (FALSE): Masked - 0x1 (TRUE): Enabled
    [6] DATA_END_BIT_ERR_STAT_EN — Data End Bit Error Status Enable (SD/eMMC Mode only). Values: - 0x0 (FALSE): Masked - 0x1 (TRUE): Enabled
    [5] DATA_CRC_ERR_STAT_EN — Data CRC Error Status Enable (SD/eMMC Mode only) Values: - 0x0 (FALSE): Masked - 0x1 (TRUE): Enabled
    [4] DATA_TOUT_ERR_STAT_EN — Data Timeout Error Status Enable (SD/eMMC Mode only) Values: - 0x0 (FALSE): Masked - 0x1 (TRUE): Enabled
    [3] CMD_IDX_ERR_STAT_EN — Command Index Error Status Enable (SD/eMMC Mode only) Values: - 0x0 (FALSE): Masked - 0x1 (TRUE): Enabled
    [2] CMD_END_BIT_ERR_STAT_EN — Command End Bit Error Status Enable (SD/eMMC Mode only) Values: - 0x0 (FALSE): Masked - 0x1 (TRUE): Enabled
    [1] CMD_CRC_ERR_STAT_EN — ommand CRC Error Status Enable (SD/eMMC Mode only) Values: - 0x0 (FALSE): Masked - 0x1 (TRUE): Enabled
    [0] CMD_TOUT_ERR_STAT_EN — Command Timeout Error Status Enable (SD/eMMC Mode only). Values: - 0x0 (FALSE): Masked - 0x1 (TRUE): Enabled
  0x38 NORMAL_INT_SIGNAL_EN_R 16-bit — Normal Interrupt Signal Enable Register
    [14] CQE_EVENT_SIGNAL_EN — Command Queuing Engine Event Signal Enable Values: - 0x0 (FALSE): Masked - 0x1 (TRUE): Enabled
    [13] FX_EVENT_SIGNAL_EN — FX Event Signal Enable Values: - 0x0 (FALSE): Masked - 0x1 (TRUE): Enabled
    [12] RE_TUNE_EVENT_SIGNAL_EN
    [11] INT_C_SIGNAL_EN
    [10] INT_B_SIGNAL_EN
    [9] INT_A_SIGNAL_EN
    [8] CARD_INTERRUPT_SIGNAL_EN — Card Interrupt Signal Enable Values: - 0x0 (FALSE): Masked - 0x1 (TRUE): Enabled
    [7] CARD_REMOVAL_SIGNAL_EN — Card Removal Signal Enable Values: - 0x0 (FALSE): Masked - 0x1 (TRUE): Enabled
    [6] CARD_INSERTION_SIGNAL_EN — Card Insertion Signal Enable Values: - 0x0 (FALSE): Masked - 0x1 (TRUE): Enabled
    [5] BUF_RD_READY_SIGNAL_EN — Buffer Read Ready Signal Enable Values: - 0x0 (FALSE): Masked - 0x1 (TRUE): Enabled
    [4] BUF_WR_READY_SIGNAL_EN — Buffer Write Ready Signal Enable Values: - 0x0 (FALSE): Masked - 0x1 (TRUE): Enabled
    [3] DMA_INTERRUPT_SIGNAL_EN — DMA Interrupt Signal Enable Values: - 0x0 (FALSE): Masked - 0x1 (TRUE): Enabled
    [2] BGAP_EVENT_SIGNAL_EN — Block Gap Event Signal Enable Values: - 0x0 (FALSE): Masked - 0x1 (TRUE): Enabled
    [1] XFER_COMPLETE_SIGNAL_EN — Transfer Complete Signal Enable Values: - 0x0 (FALSE): Masked - 0x1 (TRUE): Enabled
    [0] CMD_COMPLETE_SIGNAL_EN — Command Complete Signal Enable Values: - 0x0 (FALSE): Masked - 0x1 (TRUE): Enabled
  0x3A ERROR_INT_SIGNAL_EN_R 16-bit — Error Interrupt Signal Enable Register
    [15] VENDOR_ERR_SIGNAL_EN3
    [14] VENDOR_ERR_SIGNAL_EN2
    [13] VENDOR_ERR_SIGNAL_EN1
    [12] BOOT_ACK_ERR_SIGNAL_EN — Boot Acknowledgment Error (eMMC Mode only). Setting this bit to 1 enables generating interrupt signal when Boot Acknowledgement Error in Error Interrupt Status register is set. Values: - 0x0 (FALSE): Masked - 0x1 (TRUE): Enabled
    [11] RESP_ERR_SIGNAL_EN — Response Error Signal Enable (SD Mode only) Values: - 0x0 (FALSE): Masked - 0x1 (TRUE): Enabled
    [10] TUNING_ERR_SIGNAL_EN
    [9] ADMA_ERR_SIGNAL_EN — ADMA Error Signal Enable Values: - 0x0 (FALSE): Masked - 0x1 (TRUE): Enabled
    [8] AUTO_CMD_ERR_SIGNAL_EN — Auto CMD Error Signal Enable (SD/eMMC Mode only) Values: - 0x0 (FALSE): Masked - 0x1 (TRUE): Enabled
    [7] CUR_LMT_ERR_SIGNAL_EN — Current Limit Error Signal Enable Values: - 0x0 (FALSE): Masked - 0x1 (TRUE): Enabled
    [6] DATA_END_BIT_ERR_SIGNAL_EN — Data End Bit Error Signal Enable (SD/eMMC Mode only) Values: - 0x0 (FALSE): Masked - 0x1 (TRUE): Enabled
    [5] DATA_CRC_ERR_SIGNAL_EN — Data CRC Error Signal Enable (SD/eMMC Mode only) Values: - 0x0 (FALSE): Masked - 0x1 (TRUE): Enabled
    [4] DATA_TOUT_ERR_SIGNAL_EN — Data Timeout Error Signal Enable (SD/eMMC Mode only) Values: - 0x0 (FALSE): Masked - 0x1 (TRUE): Enabled
    [3] CMD_IDX_ERR_SIGNAL_EN — Command Index Error Signal Enable (SD/eMMC Mode only) Values: - 0x0 (FALSE): No error - 0x1 (TRUE): Error
    [2] CMD_END_BIT_ERR_SIGNAL_EN — Command End Bit Error Signal Enable (SD/eMMC Mode only) Values: - 0x0 (FALSE): Masked - 0x1 (TRUE): Enabled
    [1] CMD_CRC_ERR_SIGNAL_EN — Command CRC Error Signal Enable (SD/eMMC Mode only) Values: - 0x0 (FALSE): Masked - 0x1 (TRUE): Enabled
    [0] CMD_TOUT_ERR_SIGNAL_EN — Command Timeout Error Signal Enable (SD/eMMC Mode only) Values: - 0x0 (FALSE): Masked - 0x1 (TRUE): Enabled
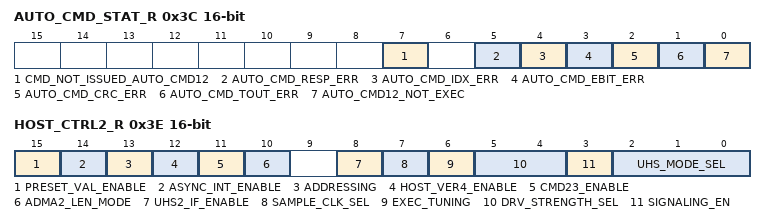
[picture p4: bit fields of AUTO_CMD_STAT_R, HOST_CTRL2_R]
  0x3C AUTO_CMD_STAT_R 16-bit ro — Auto CMD Status Register
    [7] CMD_NOT_ISSUED_AUTO_CMD12 — Command Not Issued By Auto CMD12 Error If this bit is set to 1, CMD_wo_DAT is not executed due to an Auto CMD12 Error (D04-D01) in this register. This bit is set to 0 when Auto CMD Error is generated by Auto CMD23. Values: - 0x1 (TRUE): Not Issued - 0x0 (FALSE): No Error
    [5] AUTO_CMD_RESP_ERR — Auto CMD Response Error This bit is set when Response Error Check Enable in the Transfer Mode register is set to 1 and an error is detected in R1 response of either Auto CMD12 or CMD13. This status is ignored if any bit between D00 to D04 is set to 1. Values: - 0x1 (TRUE): Error - 0x0 (FALSE): No Error
    [4] AUTO_CMD_IDX_ERR — Auto CMD Index Error This bit is set if the command index error occurs in response to a command. Values: - 0x1 (TRUE): Error - 0x0 (FALSE): No Error
    [3] AUTO_CMD_EBIT_ERR — Auto CMD End Bit Error This bit is set when detecting that the end bit of command response is 0. Values: - 0x1 (TRUE): End Bit Error Generated - 0x0 (FALSE): No Error
    [2] AUTO_CMD_CRC_ERR — Auto CMD CRC Error This bit is set when detecting a CRC error in the command response. Values: - 0x1 (TRUE): CRC Error Generated - 0x0 (FALSE): No Error
    [1] AUTO_CMD_TOUT_ERR — Auto CMD Timeout Error This bit is set if no response is returned with 64 SDCLK cycles from the end bit of the command. If this bit is set to 1, error status bits (D04-D01) are meaningless. Values: - 0x1 (TRUE): Time out - 0x0 (FALSE): No Error
    [0] AUTO_CMD12_NOT_EXEC — Auto CMD12 Not Executed If multiple memory block data transfer is not started due to a command error, this bit is not set because it is not necessary to issue an Auto CMD12. Setting this bit to 1 means that the Host Controller cannot issue Auto CMD12 to stop multiple memory block data transfer, due to some error. If this bit is set to 1, error status bits (D04-D01) is meaningless. This bit is set to 0 when Auto CMD Error is generated by Auto CMD23. Values: - 0x1 (TRUE): Not Executed - 0x0 (FALSE): Executed
  0x3E HOST_CTRL2_R 16-bit — Host Control 2 Register
    [15] PRESET_VAL_ENABLE
    [14] ASYNC_INT_ENABLE — Asynchronous Interrupt Enable This bit can be set if a card supports asynchronous interrupts and Asynchronous Interrupt Support is set to 1 in the Capabilities register. Values: - 0x0 (FALSE): Disabled - 0x1 (TRUE): Enabled
    [13] ADDRESSING
    [12] HOST_VER4_ENABLE — Host Version 4 Enable This bit selects either Version 3.00 compatible mode or Version 4 mode. Functions of following fields are modified for Host Version 4 mode: - SDMA Address: SDMA uses ADMA System Address (05Fh-058h) instead of SDMA System Address register (003h-000h) - ADMA2/ADMA3 selection: ADMA3 is selected by DMA select in Host Control 1 register - 32-bit Block Count: SDMA System Address register (003h-000h) is modified to 32-bit Block Count register Note: It is recommended not to program ADMA3 Integrated Descriptor Address registers and Command Queuing registers (if applicable) while operating in Host version less than 4 mode (Host Version 4 Enable = 0). Values: - 0x0 (FALSE): Version 3.00 compatible mode - 0x1 (TRUE): Version 4 mode
    [11] CMD23_ENABLE — CMD23 Enable If the card supports CMD23, this bit is set to 1. This bit is used to select Auto CMD23 or Auto CMD12 for ADMA3 data transfer. Values: - 0x0 (FALSE): Auto CMD23 is disabled - 0x1 (TRUE): Auto CMD23 is enabled
    [10] ADMA2_LEN_MODE — ADMA2 Length Mode This bit selects ADMA2 Length mode to be either 16-bit or 26-bit. Values: - 0x0 (FALSE): 16-bit Data Length Mode - 0x1 (TRUE): 26-bit Data Length Mode
    [8] UHS2_IF_ENABLE
    [7] SAMPLE_CLK_SEL
    [6] EXEC_TUNING
    [5:4] DRV_STRENGTH_SEL — Driver Strength Select These bits are used to select the Host Controller output driver in 1.8V signaling UHS-I/eMMC speed modes. The value is reflected on the io_drive_strength[1:0] output. - 0x0 (TYPEB): Driver TYPEB is selected - 0x1 (TYPEA): Driver TYPEA is selected - 0x2 (TYPEC): Driver TYPEC is selected - 0x3 (TYPED): Driver TYPED is selected
    [3] SIGNALING_EN — 1.8V Signaling Enable This bit controls voltage regulator for I/O cell in SD UHS-I mode. Setting this bit from 0 to 1 starts changing the signal voltage from 3.3V to 1.8V. Host Controller clears this bit if switching to 1.8V signaling fails per protocol. The value is reflected on the io_volt_sel output which can then be used to change an external regulator to supply 1.8V instead of 3.3V on the VDDIO pin associated with the CLK/CMD/DAT signals. Note: This bit must be set for all UHS-I speed modes (SDR12/SDR25/SDR50/DDR50). Values: - 0x0 (V_3_3): 3.3V Signalling - 0x1 (V_1_8): 1.8V Signalling
    [2:0] UHS_MODE_SEL
